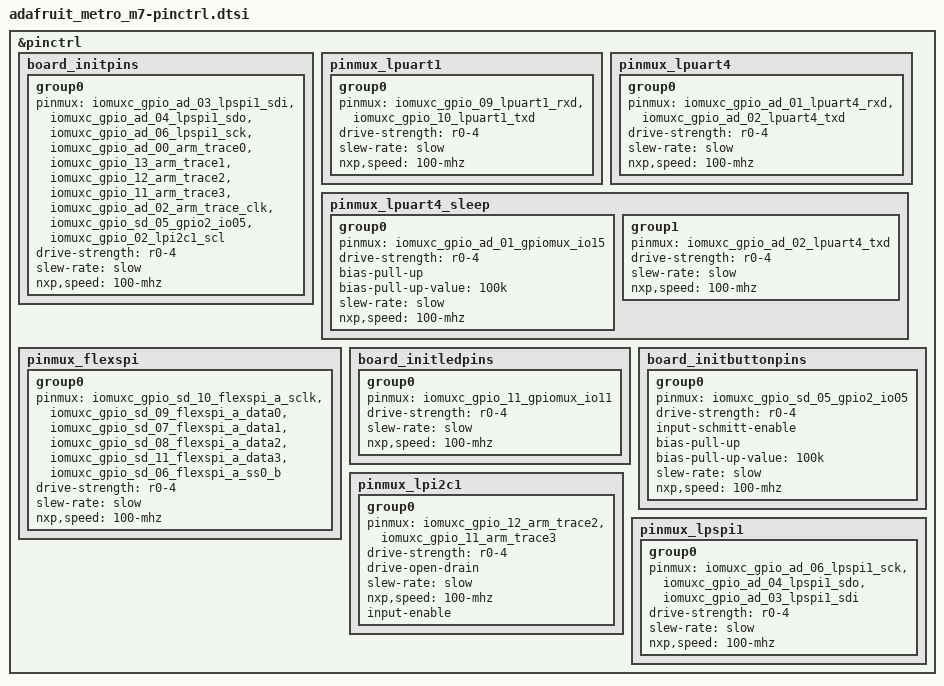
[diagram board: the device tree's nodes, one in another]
/*
 * Copyright (c) 2024, George White
 * Based on code generated by gen_board_pinctrl.py from metro_m7_1011_sd.mex in
 * the TinyUF2 project, with the following copyright information and license:
 *
 * MIT License
 *
 * Copyright (c) 2020 Ha Thach
 *
 * Permission is hereby granted, free of charge, to any person obtaining a copy
 * of this software and associated documentation files (the "Software"), to deal
 * in the Software without restriction, including without limitation the rights
 * to use, copy, modify, merge, publish, distribute, sublicense, and/or sell
 * copies of the Software, and to permit persons to whom the Software is
 * furnished to do so, subject to the following conditions:
 *
 * The above copyright notice and this permission notice shall be included in all
 * copies or substantial portions of the Software.
 *
 * THE SOFTWARE IS PROVIDED "AS IS", WITHOUT WARRANTY OF ANY KIND, EXPRESS OR
 * IMPLIED, INCLUDING BUT NOT LIMITED TO THE WARRANTIES OF MERCHANTABILITY,
 * FITNESS FOR A PARTICULAR PURPOSE AND NONINFRINGEMENT. IN NO EVENT SHALL THE
 * AUTHORS OR COPYRIGHT HOLDERS BE LIABLE FOR ANY CLAIM, DAMAGES OR OTHER
 * LIABILITY, WHETHER IN AN ACTION OF CONTRACT, TORT OR OTHERWISE, ARISING FROM,
 * OUT OF OR IN CONNECTION WITH THE SOFTWARE OR THE USE OR OTHER DEALINGS IN THE
 * SOFTWARE.
 *
 */

#include <nxp/nxp_imx/rt/mimxrt1011dae5a-pinctrl.dtsi>

&pinctrl {
	board_initpins: board_initpins {
		group0 {
			pinmux = <&iomuxc_gpio_ad_03_lpspi1_sdi>,
				<&iomuxc_gpio_ad_04_lpspi1_sdo>,
				<&iomuxc_gpio_ad_06_lpspi1_sck>,
				<&iomuxc_gpio_ad_00_arm_trace0>,
				<&iomuxc_gpio_13_arm_trace1>,
				<&iomuxc_gpio_12_arm_trace2>,
				<&iomuxc_gpio_11_arm_trace3>,
				<&iomuxc_gpio_ad_02_arm_trace_clk>,
				<&iomuxc_gpio_sd_05_gpio2_io05>,
				<&iomuxc_gpio_02_lpi2c1_scl>;
			drive-strength = "r0-4";
			slew-rate = "slow";
			nxp,speed = "100-mhz";
		};
	};

	pinmux_lpuart1: pinmux_lpuart1 {
		group0 {
			pinmux = <&iomuxc_gpio_09_lpuart1_rxd>,
				<&iomuxc_gpio_10_lpuart1_txd>;
			drive-strength = "r0-4";
			slew-rate = "slow";
			nxp,speed = "100-mhz";
		};
	};

	pinmux_lpuart4: pinmux_lpuart4 {
		group0 {
			pinmux = <&iomuxc_gpio_ad_01_lpuart4_rxd>,
				<&iomuxc_gpio_ad_02_lpuart4_txd>;
			drive-strength = "r0-4";
			slew-rate = "slow";
			nxp,speed = "100-mhz";
		};
	};

	pinmux_lpuart4_sleep: pinmux_lpuart4_sleep {
		group0 {
			pinmux = <&iomuxc_gpio_ad_01_gpiomux_io15>;
			drive-strength = "r0-4";
			bias-pull-up; /* TODO(galexite): check values for these */
			bias-pull-up-value = "100k";
			slew-rate = "slow";
			nxp,speed = "100-mhz";
		};
		group1 {
			pinmux = <&iomuxc_gpio_ad_02_lpuart4_txd>;
			drive-strength = "r0-4";
			slew-rate = "slow";
			nxp,speed = "100-mhz";
		};
	};

	pinmux_flexspi: pinmux_flexspi {
		group0 {
			pinmux = <&iomuxc_gpio_sd_10_flexspi_a_sclk>,
				<&iomuxc_gpio_sd_09_flexspi_a_data0>,
				<&iomuxc_gpio_sd_07_flexspi_a_data1>,
				<&iomuxc_gpio_sd_08_flexspi_a_data2>,
				<&iomuxc_gpio_sd_11_flexspi_a_data3>,
				<&iomuxc_gpio_sd_06_flexspi_a_ss0_b>;
			drive-strength = "r0-4";
			slew-rate = "slow";
			nxp,speed = "100-mhz";
		};
	};

	board_initledpins: board_initledpins {
		group0 {
			pinmux = <&iomuxc_gpio_11_gpiomux_io11>;
			drive-strength = "r0-4";
			slew-rate = "slow";
			nxp,speed = "100-mhz";
		};
	};

	board_initbuttonpins: board_initbuttonpins {
		group0 {
			pinmux = <&iomuxc_gpio_sd_05_gpio2_io05>;
			drive-strength = "r0-4";
			input-schmitt-enable;
			bias-pull-up;
			bias-pull-up-value = "100k";
			slew-rate = "slow";
			nxp,speed = "100-mhz";
		};
	};

	pinmux_lpi2c1: pinmux_lpi2c1 {
		group0 {
			pinmux = <&iomuxc_gpio_12_arm_trace2>,
				<&iomuxc_gpio_11_arm_trace3>;
			drive-strength = "r0-4";
			drive-open-drain;
			slew-rate = "slow";
			nxp,speed = "100-mhz";
			input-enable;
		};
	};

	pinmux_lpspi1: pinmux_lpspi1 {
		group0 {
			pinmux = <&iomuxc_gpio_ad_06_lpspi1_sck>,
				<&iomuxc_gpio_ad_04_lpspi1_sdo>,
				<&iomuxc_gpio_ad_03_lpspi1_sdi>;
			drive-strength = "r0-4";
			slew-rate = "slow";
			nxp,speed = "100-mhz";
		};
	};
};
